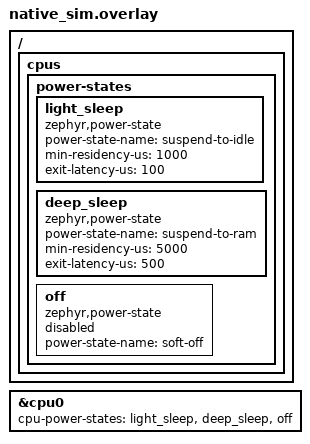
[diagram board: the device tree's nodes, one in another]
/*
 * Copyright (c) 2026 Rithic Chellaram Hariharan
 *
 * SPDX-License-Identifier: Apache-2.0
 *
 * Light (suspend-to-idle) and deep (suspend-to-ram) context-retaining states
 * for native_sim.
 */

/ {
	cpus {
		power-states {
			light_sleep: light_sleep {
				compatible = "zephyr,power-state";
				power-state-name = "suspend-to-idle";
				min-residency-us = <1000>;
				exit-latency-us = <100>;
			};

			deep_sleep: deep_sleep {
				compatible = "zephyr,power-state";
				power-state-name = "suspend-to-ram";
				min-residency-us = <5000>;
				exit-latency-us = <500>;
			};

			off: off {
				compatible = "zephyr,power-state";
				power-state-name = "soft-off";
				status = "disabled";
			};
		};
	};
};

&cpu0 {
	cpu-power-states = <&light_sleep &deep_sleep &off>;
};
